# STM32G534 register map
File version: 2.0.0
CPU: CM33 r0p4, little endian, MPU, FPU, 4 interrupt priority bits
Registers are 32-bit, read-write, reset 0x0 unless marked. A register's access mark holds for its fields unless they carry their own. Offsets are from the block's base; [hi:lo] are bit positions; {n}, {i} and the like mark numbered series; 'fields as' and 'values as' point back to an identical list.

## EXTI — EXTI address block description
Base 0x44022000
Same registers: EXTI_S 0x54022000
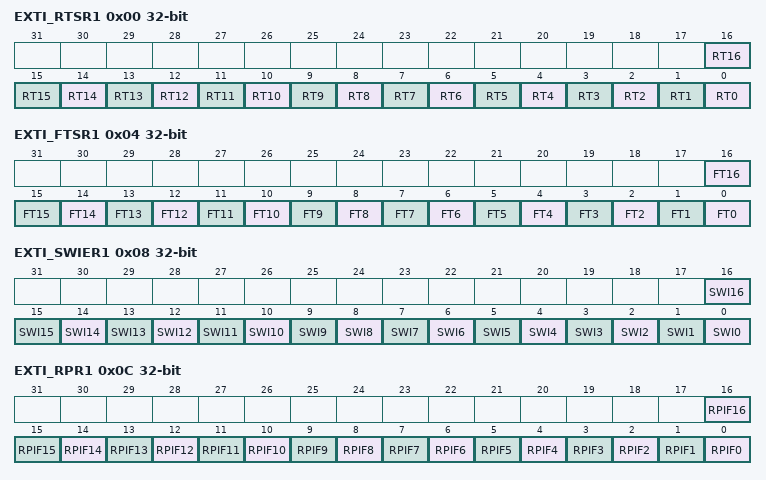
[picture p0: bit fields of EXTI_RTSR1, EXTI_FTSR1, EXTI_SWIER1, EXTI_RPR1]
0x00 EXTI_RTSR1 — EXTI rising trigger selection register
  [all] fields
    0=Rising trigger disabled (for event and interrupt) for input line; 1=Rising trigger enabled (for event and interrupt) for input line
  [n] RT{n} (n=0..16) — Rising trigger event configuration bit of configurable event input x
0x04 EXTI_FTSR1 — EXTI falling trigger selection register
  [all] fields
    0=Falling trigger disabled (for event and Interrupt) for input line; 1=Falling trigger enabled (for event and Interrupt) for input line
  [n] FT{n} (n=0..16) — Falling trigger event configuration bit of configurable event input x
0x08 EXTI_SWIER1 — EXTI software interrupt event register
  [all] fields
    0=Writing 0 has no effect; 1=Writing 1 triggers a rising edge event on event x
  [n] SWI{n} (n=0..16) — Software interrupt on event x
0x0C EXTI_RPR1 — EXTI rising edge pending register
  [all] fields
    0=No rising edge trigger request occurred; 1=Rising edge trigger request occurred
  [n] RPIF{n} (n=0..16) — configurable event inputs x rising edge pending bit
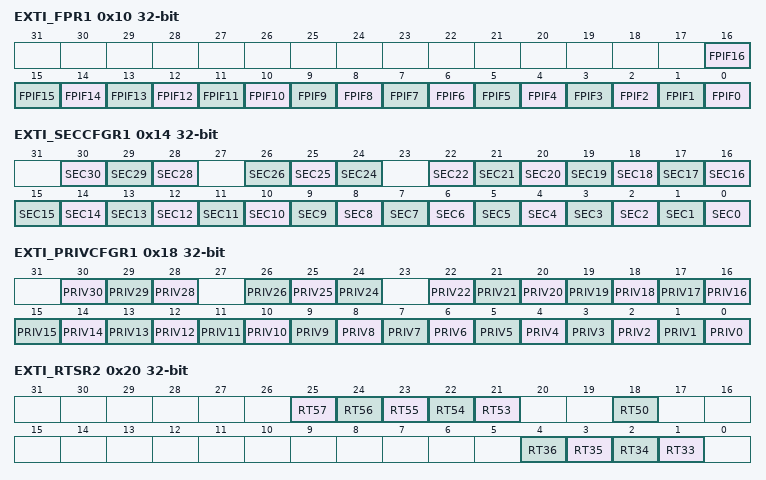
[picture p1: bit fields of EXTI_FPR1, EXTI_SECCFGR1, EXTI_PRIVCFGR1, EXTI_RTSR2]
0x10 EXTI_FPR1 — EXTI falling edge pending register
  [all] fields
    0=No falling edge trigger request occurred; 1=Falling edge trigger request occurred
  [n] FPIF{n} (n=0..16) — configurable event inputs x falling edge pending bit
0x14 EXTI_SECCFGR1 — EXTI security configuration register
  [all] fields
    0=Event security disabled (nonsecure); 1=Event security enabled (secure)
  [30] SEC30 — Security enable on event input x
  [29] SEC29 — Security enable on event input x
  [28] SEC28 — Security enable on event input x
  [26] SEC26 — Security enable on event input x
  [25] SEC25 — Security enable on event input x
  [24] SEC24 — Security enable on event input x
  [n] SEC{n} (n=0..22) — Security enable on event input x
0x18 EXTI_PRIVCFGR1 — EXTI privilege configuration register
  [all] fields
    0=Event privilege disabled (unprivileged); 1=Event privilege enabled (privileged)
  [30] PRIV30 — Security enable on event input x
  [29] PRIV29 — Security enable on event input x
  [28] PRIV28 — Security enable on event input x
  [26] PRIV26 — Security enable on event input x
  [25] PRIV25 — Security enable on event input x
  [24] PRIV24 — Security enable on event input x
  [n] PRIV{n} (n=0..22) — Security enable on event input x
0x20 EXTI_RTSR2 — EXTI rising trigger selection register 2
  [all] fields
    values as the fields of EXTI_RTSR1
  [n-32] RT{n} (n=53..57) — Rising trigger event configuration bit of configurable event input x
  [18] RT50 — Rising trigger event configuration bit of configurable event input xless thansup>(1)less than/sup>
  [n-32] RT{n} (n=33..36) — Rising trigger event configuration bit of configurable event input xless thansup>(1)less than/sup>
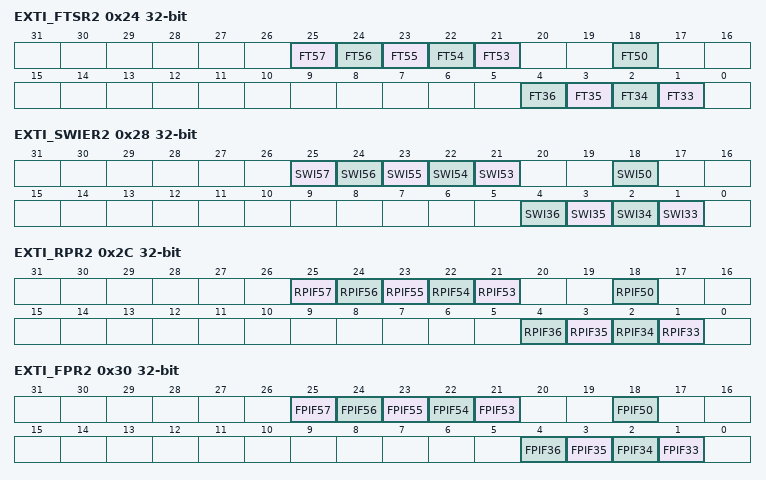
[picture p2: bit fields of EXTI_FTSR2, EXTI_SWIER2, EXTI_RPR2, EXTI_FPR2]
0x24 EXTI_FTSR2 — EXTI falling trigger selection register 2
  [all] fields
    values as the fields of EXTI_FTSR1
  [n-32] FT{n} (n=53..57) — Falling trigger event configuration bit of configurable event input x
  [18] FT50 — Falling trigger event configuration bit of configurable event input xless thansup>(1)less than/sup>
  [n-32] FT{n} (n=33..36) — Falling trigger event configuration bit of configurable event input xless thansup>(1)less than/sup>
0x28 EXTI_SWIER2 — EXTI software interrupt event register 2
  [all] fields
    values as the fields of EXTI_SWIER1
  [n-32] SWI{n} (n=53..57) — Software interrupt on event x
  [18] SWI50 — Software interrupt on event x
  [n-32] SWI{n} (n=33..36) — Software interrupt on event x
0x2C EXTI_RPR2 — EXTI rising edge pending register 2
  [all] fields
    values as the fields of EXTI_RPR1
  [n-32] RPIF{n} (n=53..57) — configurable event inputs x rising edge pending bit
  [18] RPIF50 — configurable event inputs x rising edge pending bit
  [n-32] RPIF{n} (n=33..36) — configurable event inputs x rising edge pending bit
0x30 EXTI_FPR2 — EXTI falling edge pending register 2
  [all] fields
    values as the fields of EXTI_FPR1
  [n-32] FPIF{n} (n=53..57) — configurable event inputs x falling edge pending bit
  [18] FPIF50 — configurable event inputs x falling edge pending bit
  [n-32] FPIF{n} (n=33..36) — configurable event inputs x falling edge pending bit
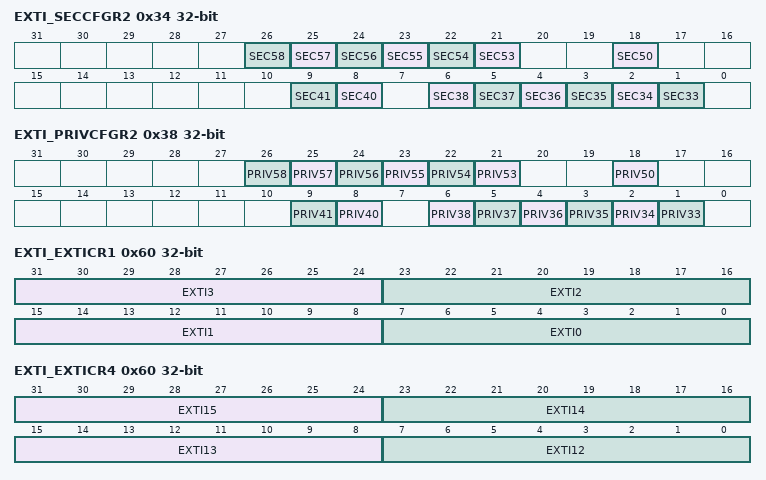
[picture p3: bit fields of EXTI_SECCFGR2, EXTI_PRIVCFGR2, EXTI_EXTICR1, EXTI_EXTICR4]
0x34 EXTI_SECCFGR2 — EXTI security configuration register 2
  [all] fields
    values as the fields of EXTI_SECCFGR1
  [n-32] SEC{n} (n=53..58) — Security enable on event input x
  [18] SEC50 — Security enable on event input x
  [9] SEC41 — Security enable on event input x
  [8] SEC40 — Security enable on event input x
  [n-32] SEC{n} (n=33..38) — Security enable on event input x
0x38 EXTI_PRIVCFGR2 — EXTI privilege configuration register 2
  [all] fields
    values as the fields of EXTI_PRIVCFGR1
  [n-32] PRIV{n} (n=53..58) — Security enable on event input x
  [18] PRIV50 — Security enable on event input x
  [9] PRIV41 — Security enable on event input x
  [8] PRIV40 — Security enable on event input x
  [n-32] PRIV{n} (n=33..38) — Security enable on event input x
0x60 EXTI_EXTICR1 — EXTI external interrupt selection register
  [31:24] EXTI3 — EXTI3 GPIO port selection
    0=PA3 pin; 1=PB3 pin; 2=PC3 pin; 3=PD3 pin; 4=PE3 pin; 5=PF3 pin; 6=PG3 pin
  [23:16] EXTI2 — EXTI2 GPIO port selection
    0=PA2 pin; 1=PB2 pin; 2=PC2 pin; 3=PD2 pin; 4=PE2 pin; 5=PF2 pin; 6=PG2 pin
  [15:8] EXTI1 — EXTI1 GPIO port selection
    0=PA1 pin; 1=PB1 pin; 2=PC1 pin; 3=PD1 pin; 7=PH1 pin
  [7:0] EXTI0 — EXTI0 GPIO port selection
    0=PA0 pin; 1=PB0 pin; 2=PC0 pin; 3=PD0 pin; 5=PF0 pin; 7=PH0 pin
0x60 EXTI_EXTICR4 (alternate view of EXTI_EXTICR1) — EXTI external interrupt selection register
  [31:24] EXTI15 — EXTI15 GPIO port selection
    0=PA15 pin; 1=PB15 pin; 2=PC15 pin; 3=PD15 pin; 4=PE15 pin; 5=PF15 pin
  [23:16] EXTI14 — EXTI14 GPIO port selection
    0=PA14 pin; 1=PB14 pin; 2=PC14 pin; 3=PD14 pin; 4=PE14 pin; 5=PF14 pin; 6=PG14 pin
  [15:8] EXTI13 — EXTI13 GPIO port selection
    0=PA13 pin; 1=PB13 pin; 2=PC13 pin; 3=PD13 pin; 4=PE13 pin; 5=PF13 pin; 6=PG13 pin
  [7:0] EXTI12 — EXTI12 GPIO port selection
    0=PA12 pin; 1=PB12 pin; 2=PC12 pin; 3=PD12 pin; 4=PE12 pin; 5=PF12 pin; 6=PG12 pin
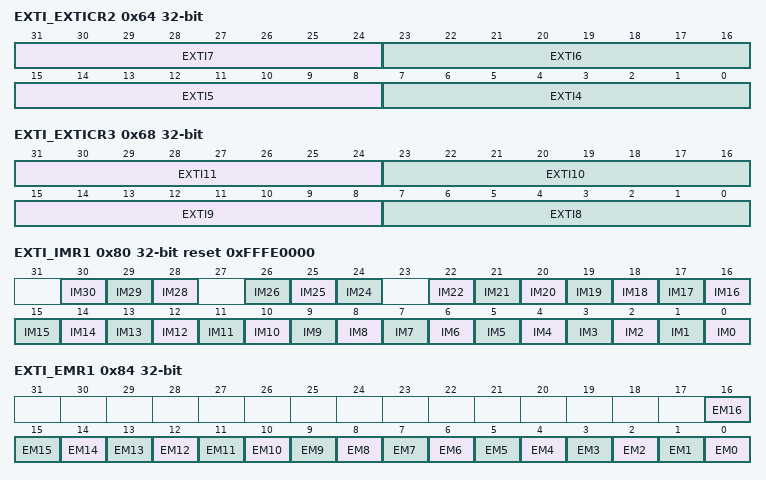
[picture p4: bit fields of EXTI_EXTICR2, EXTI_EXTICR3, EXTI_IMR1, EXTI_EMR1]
0x64 EXTI_EXTICR2 — EXTI external interrupt selection register
  [31:24] EXTI7 — EXTI7 GPIO port selection
    0=PA7 pin; 1=PB7 pin; 2=PC7 pin; 3=PD7 pin; 4=PE7 pin; 5=PF7 pin
  [23:16] EXTI6 — EXTI6 GPIO port selection
    0=PA6 pin; 1=PB6 pin; 2=PC6 pin; 3=PD6 pin; 4=PE6 pin
  [15:8] EXTI5 — EXTI5 GPIO port selection
    0=PA5 pin; 1=PB5 pin; 2=PC5 pin; 3=PD5 pin; 4=PE5 pin; 6=PG5 pin; 7=PH5 pin
  [7:0] EXTI4 — EXTI4 GPIO port selection
    0=PA4 pin; 1=PB4 pin; 2=PC4 pin; 3=PD4 pin; 4=PE4 pin; 5=PF4 pin; 6=PG4 pin
0x68 EXTI_EXTICR3 — EXTI external interrupt selection register
  [31:24] EXTI11 — EXTI11 GPIO port selection
    0=PA11 pin; 1=PB11 pin; 2=PC11 pin; 3=PD11 pin; 4=PE11 pin; 5=PF11 pin; 6=PG11 pin
  [23:16] EXTI10 — EXTI10 GPIO port selection
    0=PA10 pin; 1=PB10 pin; 2=PC10 pin; 3=PD10 pin; 4=PE10 pin; 5=PF10 pin; 6=PG10 pin
  [15:8] EXTI9 — EXTI9 GPIO port selection
    0=PA9 pin; 1=PB9 pin; 2=PC9 pin; 3=PD9 pin; 4=PE9 pin; 5=PF9 pin; 6=PG9 pin
  [7:0] EXTI8 — EXTI8 GPIO port selection
    0=PA8 pin; 2=PC8 pin; 3=PD8 pin; 4=PE8 pin; 5=PF8 pin
0x70 EXTI_LOCKR — EXTI lock register
  [0] LOCK — Global security and privilege configuration registers (EXTI_SECCFGR and EXTI_PRIVCFGR) lock
    0=Security and privilege configuration open, can be modified; 1=Security and privilege configuration locked, can no longer be modified
0x80 EXTI_IMR1 reset 0xFFFE0000 — EXTI CPU wake-up with interrupt mask register
  [all] fields
    0=Wake-up with interrupt request from input event x is masked; 1=Wake-up with interrupt request from input event x is unmasked
  [30] IM30 — CPU wake-up with interrupt mask on event input x
  [29] IM29 — CPU wake-up with interrupt mask on event input x
  [28] IM28 — CPU wake-up with interrupt mask on event input x
  [26] IM26 — CPU wake-up with interrupt mask on event input x
  [25] IM25 — CPU wake-up with interrupt mask on event input x
  [24] IM24 — CPU wake-up with interrupt mask on event input x
  [n] IM{n} (n=0..22) — CPU wake-up with interrupt mask on event input x
0x84 EXTI_EMR1 — EXTI CPU wake-up with event mask register
  [all] fields
    0=Wake-up with event generation from Line x is masked; 1=Wake-up with event generation from Line x is unmasked
  [n] EM{n} (n=0..16) — CPU wake-up with event generation mask on event input x
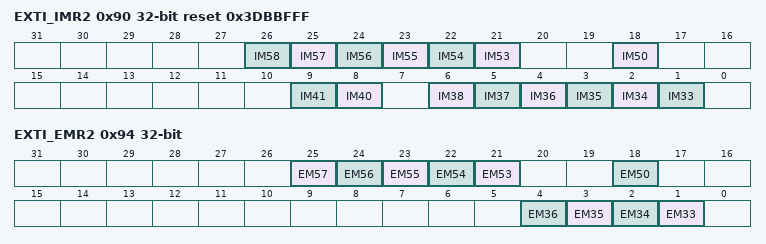
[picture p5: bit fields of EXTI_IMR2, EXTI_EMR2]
0x90 EXTI_IMR2 reset 0x3DBBFFF — EXTI CPU wake-up with interrupt mask register 2
  [all] fields
    values as the fields of EXTI_IMR1
  [n-32] IM{n} (n=53..58) — CPU wake-up with interrupt mask on event input x
  [18] IM50 — CPU wake-up with interrupt mask on event input x
  [9] IM41 — CPU wake-up with interrupt mask on event input xless thansup>(1)less than/sup>
  [8] IM40 — CPU wake-up with interrupt mask on event input xless thansup>(1)less than/sup>
  [n-32] IM{n} (n=33..38) — CPU wake-up with interrupt mask on event input xless thansup>(1)less than/sup>
0x94 EXTI_EMR2 — EXTI CPU wake-up with event mask register 2
  [all] fields
    values as the fields of EXTI_EMR1
  [n-32] EM{n} (n=53..57) — CPU wake-up with event generation mask on event input x
  [18] EM50 — CPU wake-up with event generation mask on event input x
  [n-32] EM{n} (n=33..36) — CPU wake-up with event generation mask on event input x
